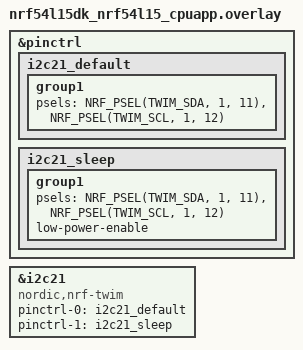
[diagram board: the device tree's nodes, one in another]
/*
 * Copyright (c) 2024 Nordic Semiconductor ASA
 *
 * SPDX-License-Identifier: LicenseRef-Nordic-5-Clause
 */

&pinctrl {
	i2c21_default: i2c21_default {
		group1 {
			psels = <NRF_PSEL(TWIM_SDA, 1, 11)>,
				<NRF_PSEL(TWIM_SCL, 1, 12)>;
		};
	};

	i2c21_sleep: i2c21_sleep {
		group1 {
			psels = <NRF_PSEL(TWIM_SDA, 1, 11)>,
				<NRF_PSEL(TWIM_SCL, 1, 12)>;
			low-power-enable;
		};
	};
};

/* Define arduino_i2c here so it is available for the shield overlay */
arduino_i2c: &i2c21 {
	compatible = "nordic,nrf-twim";
	pinctrl-0 = <&i2c21_default>;
	pinctrl-1 = <&i2c21_sleep>;
	pinctrl-names = "default", "sleep";
};
